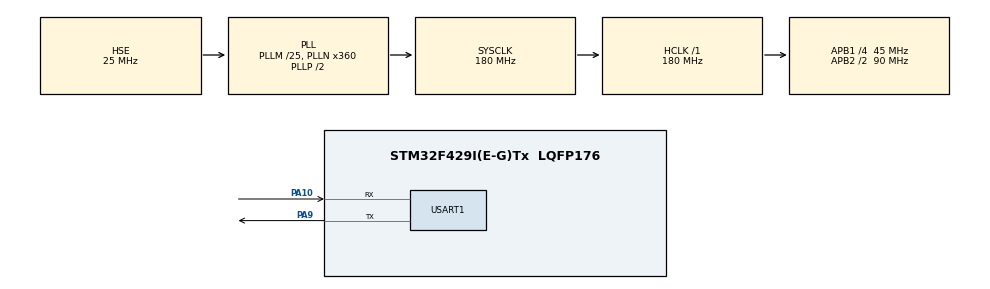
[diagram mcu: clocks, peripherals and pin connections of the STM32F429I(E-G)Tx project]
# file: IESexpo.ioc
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Mcu.Family=STM32F4
Mcu.Name=STM32F429I(E-G)Tx
Mcu.Package=LQFP176
NVIC.PriorityGroup=NVIC_PRIORITYGROUP_4
NVIC.USART1_IRQn=true\:0\:0\:false\:false\:true\:true
PA10.Mode=Asynchronous
PA10.Signal=USART1_RX
PA13.Mode=Serial_Wire
PA13.Signal=SYS_JTMS-SWDIO
PA14.Mode=Serial_Wire
PA14.Signal=SYS_JTCK-SWCLK
PA9.Mode=Asynchronous
PA9.Signal=USART1_TX
PC14/OSC32_IN.Mode=LSE-External-Oscillator
PC14/OSC32_IN.Signal=RCC_OSC32_IN
PC15/OSC32_OUT.Mode=LSE-External-Oscillator
PC15/OSC32_OUT.Signal=RCC_OSC32_OUT
PH0/OSC_IN.Mode=HSE-External-Oscillator
PH0/OSC_IN.Signal=RCC_OSC_IN
PH1/OSC_OUT.Mode=HSE-External-Oscillator
PH1/OSC_OUT.Signal=RCC_OSC_OUT
ProjectManager.HeapSize=0x200
ProjectManager.StackSize=0x400
ProjectManager.TargetToolchain=MDK-ARM V5
RCC.48MHZClocksFreq_Value=90000000
RCC.AHBFreq_Value=180000000
RCC.APB1CLKDivider=RCC_HCLK_DIV4
RCC.APB1Freq_Value=45000000
RCC.APB1TimFreq_Value=90000000
RCC.APB2CLKDivider=RCC_HCLK_DIV2
RCC.APB2Freq_Value=90000000
RCC.APB2TimFreq_Value=180000000
RCC.CortexFreq_Value=180000000
RCC.HCLKFreq_Value=180000000
RCC.HSE_VALUE=25000000
RCC.HSI_VALUE=16000000
RCC.PLLM=25
RCC.PLLN=360
RCC.PLLSourceVirtual=RCC_PLLSOURCE_HSE
RCC.SYSCLKFreq_VALUE=180000000
RCC.SYSCLKSource=RCC_SYSCLKSOURCE_PLLCLK
RCC.VCOOutputFreq_Value=360000000
USART1.VirtualMode=VM_ASYNC
board=custom

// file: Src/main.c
/**
  ******************************************************************************
  * @file           : main.c
  * @brief          : Main program body
  ******************************************************************************
  ** This notice applies to any and all portions of this file
  * that are not between comment pairs USER CODE BEGIN and
  * USER CODE END. Other portions of this file, whether
  * inserted by the user or by software development tools
  * are owned by their respective copyright owners.
  *
  * COPYRIGHT(c) 2018 STMicroelectronics
  *
  * Redistribution and use in source and binary forms, with or without modification,
  * are permitted provided that the following conditions are met:
  *   1. Redistributions of source code must retain the above copyright notice,
  *      this list of conditions and the following disclaimer.
  *   2. Redistributions in binary form must reproduce the above copyright notice,
  *      this list of conditions and the following disclaimer in the documentation
  *      and/or other materials provided with the distribution.
  *   3. Neither the name of STMicroelectronics nor the names of its contributors
  *      may be used to endorse or promote products derived from this software
  *      without specific prior written permission.
  *
  * THIS SOFTWARE IS PROVIDED BY THE COPYRIGHT HOLDERS AND CONTRIBUTORS "AS IS"
  * AND ANY EXPRESS OR IMPLIED WARRANTIES, INCLUDING, BUT NOT LIMITED TO, THE
  * IMPLIED WARRANTIES OF MERCHANTABILITY AND FITNESS FOR A PARTICULAR PURPOSE ARE
  * DISCLAIMED. IN NO EVENT SHALL THE COPYRIGHT HOLDER OR CONTRIBUTORS BE LIABLE
  * FOR ANY DIRECT, INDIRECT, INCIDENTAL, SPECIAL, EXEMPLARY, OR CONSEQUENTIAL
  * DAMAGES (INCLUDING, BUT NOT LIMITED TO, PROCUREMENT OF SUBSTITUTE GOODS OR
  * SERVICES; LOSS OF USE, DATA, OR PROFITS; OR BUSINESS INTERRUPTION) HOWEVER
  * CAUSED AND ON ANY THEORY OF LIABILITY, WHETHER IN CONTRACT, STRICT LIABILITY,
  * OR TORT (INCLUDING NEGLIGENCE OR OTHERWISE) ARISING IN ANY WAY OUT OF THE USE
  * OF THIS SOFTWARE, EVEN IF ADVISED OF THE POSSIBILITY OF SUCH DAMAGE.
  *
  ******************************************************************************
  */
#include "main.h"
#include "stm32f4xx_hal.h"
#include "string.h"

UART_HandleTypeDef huart1;

/* USER CODE BEGIN PV */
/* Private variables ---------------------------------------------------------*/

char start[6];
char str[]="start";

uint8_t aTxStartMessage[] = "\r\n****UART-Hyperterminal communication based on IT ****\r\nEnter 10 characters using keyboard :\r\n";
uint8_t aRxBuffer[20];

/* USER CODE END PV */

void SystemClock_Config(void);
static void MX_GPIO_Init(void);
static void MX_USART1_UART_Init(void);

/* USER CODE BEGIN PFP */
/* Private function prototypes -----------------------------------------------*/

/* USER CODE END PFP */

/* USER CODE BEGIN 0 */
#ifdef __GNUC__
  /* With GCC/RAISONANCE, small printf (option LD Linker->Libraries->Small printf
     set to 'Yes') calls __io_putchar() */
  #define PUTCHAR_PROTOTYPE int __io_putchar(int ch)
#else
  #define PUTCHAR_PROTOTYPE int fputc(int ch, FILE *f)
#endif /* __GNUC__ */
/**
  * @brief  Retargets the C library printf function to the USART.
  * @param  None
  * @retval None
  */
PUTCHAR_PROTOTYPE
{
  /* Place your implementation of fputc here */
  /* e.g. write a character to the EVAL_COM1 and Loop until the end of transmission */
  HAL_UART_Transmit(&huart1, (uint8_t *)&ch, 1, 0xFFFF);

  return ch;
}
/* USER CODE END 0 */

int main(void)
{

  /* MCU Configuration----------------------------------------------------------*/

  /* Reset of all peripherals, Initializes the Flash interface and the Systick. */
  HAL_Init();

  /* Configure the system clock */
  SystemClock_Config();

  /* Initialize all configured peripherals */
  MX_GPIO_Init();
  MX_USART1_UART_Init();
  /* USER CODE BEGIN 2 */

	//HAL_UART_Transmit_IT(&huart1, (uint8_t *)aTxStartMessage, sizeof(aTxStartMessage));
	HAL_UART_Receive_IT(&huart1, (uint8_t *)aRxBuffer, 5);
  /* USER CODE END 2 */

  /* Infinite loop */
  while (1)
  {

  /* USER CODE BEGIN 3 */
		HAL_UART_Receive_IT(&huart1, (uint8_t *)aRxBuffer, 5);
  }
  /* USER CODE END 3 */

}

void SystemClock_Config(void)
{

  RCC_OscInitTypeDef RCC_OscInitStruct;
  RCC_ClkInitTypeDef RCC_ClkInitStruct;

    /**Configure the main internal regulator output voltage
    */
  __HAL_RCC_PWR_CLK_ENABLE();

  __HAL_PWR_VOLTAGESCALING_CONFIG(PWR_REGULATOR_VOLTAGE_SCALE1);

    /**Initializes the CPU, AHB and APB busses clocks
    */
  RCC_OscInitStruct.OscillatorType = RCC_OSCILLATORTYPE_HSE;
  RCC_OscInitStruct.HSEState = RCC_HSE_ON;
  RCC_OscInitStruct.PLL.PLLState = RCC_PLL_ON;
  RCC_OscInitStruct.PLL.PLLSource = RCC_PLLSOURCE_HSE;
  RCC_OscInitStruct.PLL.PLLM = 25;
  RCC_OscInitStruct.PLL.PLLN = 360;
  RCC_OscInitStruct.PLL.PLLP = RCC_PLLP_DIV2;
  RCC_OscInitStruct.PLL.PLLQ = 4;
  if (HAL_RCC_OscConfig(&RCC_OscInitStruct) != HAL_OK)
  {
    _Error_Handler(__FILE__, __LINE__);
  }

    /**Activate the Over-Drive mode
    */
  if (HAL_PWREx_EnableOverDrive() != HAL_OK)
  {
    _Error_Handler(__FILE__, __LINE__);
  }

    /**Initializes the CPU, AHB and APB busses clocks
    */
  RCC_ClkInitStruct.ClockType = RCC_CLOCKTYPE_HCLK|RCC_CLOCKTYPE_SYSCLK
                              |RCC_CLOCKTYPE_PCLK1|RCC_CLOCKTYPE_PCLK2;
  RCC_ClkInitStruct.SYSCLKSource = RCC_SYSCLKSOURCE_PLLCLK;
  RCC_ClkInitStruct.AHBCLKDivider = RCC_SYSCLK_DIV1;
  RCC_ClkInitStruct.APB1CLKDivider = RCC_HCLK_DIV4;
  RCC_ClkInitStruct.APB2CLKDivider = RCC_HCLK_DIV2;

  if (HAL_RCC_ClockConfig(&RCC_ClkInitStruct, FLASH_LATENCY_5) != HAL_OK)
  {
    _Error_Handler(__FILE__, __LINE__);
  }

    /**Configure the Systick interrupt time
    */
  HAL_SYSTICK_Config(HAL_RCC_GetHCLKFreq()/1000);

    /**Configure the Systick
    */
  HAL_SYSTICK_CLKSourceConfig(SYSTICK_CLKSOURCE_HCLK);

  /* SysTick_IRQn interrupt configuration */
  HAL_NVIC_SetPriority(SysTick_IRQn, 0, 0);
}

/* USART1 init function */
static void MX_USART1_UART_Init(void)
{

  huart1.Instance = USART1;
  huart1.Init.BaudRate = 115200;
  huart1.Init.WordLength = UART_WORDLENGTH_8B;
  huart1.Init.StopBits = UART_STOPBITS_1;
  huart1.Init.Parity = UART_PARITY_NONE;
  huart1.Init.Mode = UART_MODE_TX_RX;
  huart1.Init.HwFlowCtl = UART_HWCONTROL_NONE;
  huart1.Init.OverSampling = UART_OVERSAMPLING_16;
  if (HAL_UART_Init(&huart1) != HAL_OK)
  {
    _Error_Handler(__FILE__, __LINE__);
  }

}

/** Configure pins as
        * Analog
        * Input
        * Output
        * EVENT_OUT
        * EXTI
*/
static void MX_GPIO_Init(void)
{

  /* GPIO Ports Clock Enable */
  __HAL_RCC_GPIOC_CLK_ENABLE();
  __HAL_RCC_GPIOH_CLK_ENABLE();
  __HAL_RCC_GPIOA_CLK_ENABLE();

}

/* USER CODE BEGIN 4 */

void HAL_UART_RxCpltCallback(UART_HandleTypeDef *huart)
{
  /* Prevent unused argument(s) compilation warning */
  UNUSED(huart);

  /* NOTE : This function should not be modified, when the callback is needed,
            the HAL_UART_RxCpltCallback can be implemented in the user file
   */
	for(int i=0;i<5;i++)
	{
		start[i]=aRxBuffer[i];
	}
	start[5]='\0';

	if(strstr(start,str))
	{
		HAL_UART_Transmit(&huart1, (uint8_t *)"HB1=0.8\n", 8,0xFFFF);
		HAL_UART_Transmit(&huart1, (uint8_t *)"HB2=0.6\n", 8,0xFFFF);
	}
	else
	{
		HAL_UART_Transmit(&huart1, (uint8_t *)"HB1=0.2\n", 8,0xFFFF);
		HAL_UART_Transmit(&huart1, (uint8_t *)"HB2=0.2\n", 8,0xFFFF);
	}
  //HAL_UART_Transmit(&huart1, (uint8_t *)aRxBuffer, 5,0xFFFF);
}

/* USER CODE END 4 */

void _Error_Handler(char *file, int line)
{
  while(1)
  {
  }
}

/************************ (C) COPYRIGHT STMicroelectronics *****END OF FILE****/
